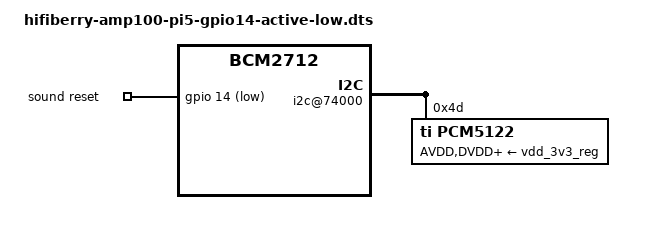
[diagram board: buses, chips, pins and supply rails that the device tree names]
/dts-v1/;
/plugin/;

/ {
    compatible = "brcm,bcm2712";
    
    fragment@0 {
        target-path = "/";
        __overlay__ {
            dacpro_osc {
                compatible = "hifiberry,dacpro-clk";
                #clock-cells = <0>;
                phandle = <0x01>;
            };
        };
    };
    
    fragment@1 {
        target = <&i2s_clk_consumer>;
        __overlay__ {
            status = "okay";
        };
    };
    
    fragment@2 {
        target-path = "/axi/pcie@1000120000/rp1/i2c@74000";
        __overlay__ {
            #address-cells = <1>;
            #size-cells = <0>;
            status = "okay";
            
            pcm5122@4d {
                #sound-dai-cells = <0>;
                compatible = "ti,pcm5122";
                reg = <0x4d>;
                clocks = <0x01>;
                AVDD-supply = <&vdd_3v3_reg>;
                DVDD-supply = <&vdd_3v3_reg>;
                CPVDD-supply = <&vdd_3v3_reg>;
                status = "okay";
            };
        };
    };
    
    fragment@3 {
        target-path = "/soc@107c000000";
        __overlay__ {
            sound {
                compatible = "hifiberry,hifiberry-dacplus";
                i2s-controller = <&i2s_clk_consumer>;
                status = "okay";
                reset-gpio = <&gpio 14 1>;  // GPIO 14, Active Low (Flag 1)
            };
        };
    };
    
    __fixups__ {
        i2s_clk_consumer = "/fragment@1:target:0", "/fragment@3/__overlay__/sound:i2s-controller:0";
        vdd_3v3_reg = "/fragment@2/__overlay__/pcm5122@4d:AVDD-supply:0", "/fragment@2/__overlay__/pcm5122@4d:DVDD-supply:0", "/fragment@2/__overlay__/pcm5122@4d:CPVDD-supply:0";
        gpio = "/fragment@3/__overlay__/sound:reset-gpio:0";
    };
    
    __local_fixups__ {
        fragment@2 {
            __overlay__ {
                pcm5122@4d {
                    clocks = <0x00>;
                };
            };
        };
    };
};

